# CY8C5888LTI_LP097 register map
File version: 0.1
CY8C58LP
Registers are 8-bit, read-write, no defined reset value unless marked. A register's access mark holds for its fields unless they carry their own. Offsets are from the block's base; lines under a group give offsets from that group; [hi:lo] are bit positions; {n}, {i} and the like mark numbered series; 'fields as' and 'values as' point back to an identical list; <NAME> marks a mode.

## Memory map
0x00000000 Comp_A
0x00000000 Comp_B
0x00000000 Status_Reg
0x00000000 Control_Reg
0x00000000 ADC_SAR_B — SAR ADC
0x00000000 UART
0x00000000 Sample_Hold_B
0x00000000 Sample_Hold_A
0x00000000 ADC_SAR_A — SAR ADC

## Status_Reg
Base 0x00000000
0x4000656B Status_Reg_STATUS_REG
0x4000658B Status_Reg_MASK_REG
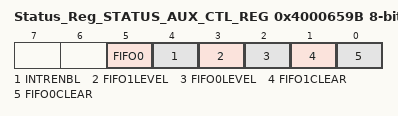
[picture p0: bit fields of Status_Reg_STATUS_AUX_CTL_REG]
0x4000659B Status_Reg_STATUS_AUX_CTL_REG
  [5] FIFO0 — FIFO0 clear
    1=ENABLED (Enable counter); 0=DISABLED (Disable counter)
  [4] INTRENBL — Enables or disables the Interrupt
    1=ENABLED (Interrupt enabled); 0=DISABLED (Interrupt disabled)
  [3] FIFO1LEVEL — FIFO level
    1=ENABLED (FIFO LVL: input mode: FIFO at least 1/2 empty; output mode: FIFO at least 1/2 full); 0=DISABLED (FIFO LVL: input mode: FIFO not full; output mode: FIFO not empty)
  [2] FIFO0LEVEL — FIFO level
    values as FIFO1LEVEL
  [1] FIFO1CLEAR — FIFO clear
    1=ENABLED (Clear FIFO state); 0=DISABLED (Normal FIFO operation)
  [0] FIFO0CLEAR — FIFO clear
    values as FIFO1CLEAR

## Control_Reg
Base 0x00000000
0x4000657B Control_Reg_CONTROL_REG

## ADC_SAR_B — SAR ADC
Base 0x00000000
0x40004616 SAR_TR0 — SAR trim register
{0x40005908+i} SAR_CSR{i} (i=0..6) — SAR status and control register {i}
0x40005B28 SAR_SW0 — SAR Analog Routing Register 0
{0x40005B28+i} SAR_SW{i} (i=2..4) — SAR Analog Routing Register {i}
0x40005B2E SAR_SW6 — SAR Analog Routing Register 6
0x40005B2F SAR_CLK — SAR Clock Selection Register
0x40005BA2 SAR_WRK 16-bit — SAR working register

## UART
Base 0x00000000
0x40006529 RX_UART_RX_ADDRESS1 — RX Address1 Register
0x40006539 RX_UART_RX_ADDRESS2 — RX Address2 Register
0x40006548 TX_UART_TX_DATA — TX Data Register
0x40006549 RX_UART_RX_DATA — RX Data Register
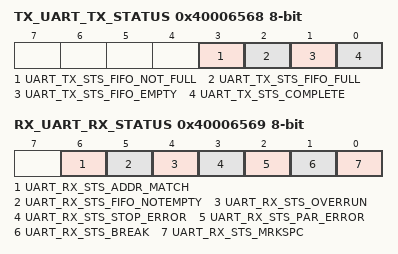
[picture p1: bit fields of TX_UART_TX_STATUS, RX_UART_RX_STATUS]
0x40006568 TX_UART_TX_STATUS — TX status register
  [3] UART_TX_STS_FIFO_NOT_FULL ro, [2] UART_TX_STS_FIFO_FULL ro, [1] UART_TX_STS_FIFO_EMPTY ro, [0] UART_TX_STS_COMPLETE ro
0x40006569 RX_UART_RX_STATUS — RX status register
  [6] UART_RX_STS_ADDR_MATCH ro, [5] UART_RX_STS_FIFO_NOTEMPTY ro, [4] UART_RX_STS_OVERRUN ro, [3] UART_RX_STS_STOP_ERROR ro, [2] UART_RX_STS_PAR_ERROR ro, [1] UART_RX_STS_BREAK ro, [0] UART_RX_STS_MRKSPC ro

## ADC_SAR_A — SAR ADC
Base 0x00000000
0x40004614 SAR_TR0 — SAR trim register
{0x40005900+i} SAR_CSR{i} (i=0..6) — SAR status and control register {i}
0x40005B20 SAR_SW0 — SAR Analog Routing Register 0
{0x40005B20+i} SAR_SW{i} (i=2..4) — SAR Analog Routing Register {i}
0x40005B26 SAR_SW6 — SAR Analog Routing Register 6
0x40005B27 SAR_CLK — SAR Clock Selection Register
0x40005BA0 SAR_WRK 16-bit — SAR working register
